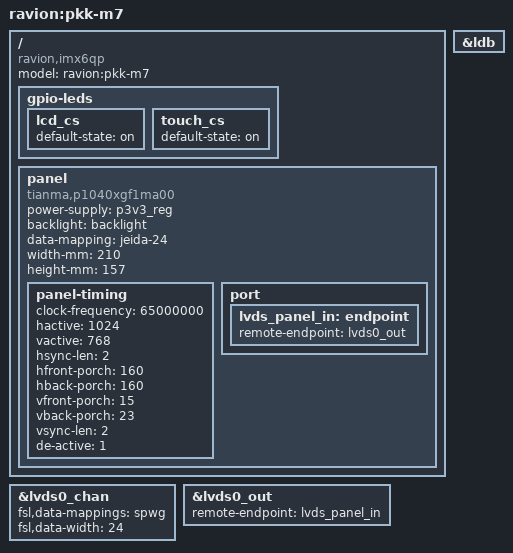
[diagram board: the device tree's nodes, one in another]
/*
 * Copyright 2018 Radioavionica Corp.
 *
 * Author: Alex A. Mihaylov <minimumlaw@rambler.ru>
 *
 * This program is free software; you can redistribute it and/or modify
 * it under the terms of the GNU General Public License version 2 as
 * published by the Free Software Foundation.
 *
 */
/dts-v1/;
#include "imx6qp.dtsi"

#include "imx6qdl-ravion-v2.dtsi"
#include "imx6qp-ravion-pkk.dtsi"

/ {
	model = "ravion:pkk-m7";
	compatible = "ravion,imx6qp", "fsl,imx6qp";

	gpio-leds { /* rotate panel */
		lcd_cs		{ default-state = "on"; };
		touch_cs	{ default-state = "on"; };
	};

	panel {
		power-supply = <&p3v3_reg>;
		backlight = <&backlight>;
		data-mapping = "jeida-24";
		compatible = "tianma,p1040xgf1ma00", "panel-lvds";
		width-mm = <210>;
		height-mm = <157>;

		panel-timing {
			clock-frequency = <65000000>;
			hactive = <1024>;
			vactive = <768>;
			hsync-len = <2>;
			hfront-porch = <160>;
			hback-porch = <160>;
			vfront-porch = <15>;
			vback-porch = <23>;
			vsync-len = <2>;
			de-active = <1>;
		};

		port {
			lvds_panel_in: endpoint {
				remote-endpoint = <&lvds0_out>;
			};
		};
	};
};

/* LVDS */
&ldb {
	status = "okay";
};

&lvds0_chan {
	fsl,data-mappings = "spwg"; /* "jeida" */
	fsl,data-width = <24>;
	status = "okay";
};

&lvds0_out {
	remote-endpoint = <&lvds_panel_in>;
};
